# R9A09G057H register map
Vendor: Renesas Electronics; File version: 1.0
Registers are 32-bit, read-write, no defined reset value unless marked. A register's access mark holds for its fields unless they carry their own. Offsets are from the block's base; [hi:lo] are bit positions; {n}, {i} and the like mark numbered series; 'fields as' and 'values as' point back to an identical list.

## R_SYSC — IO define file for sysc.
Base 0x10430000
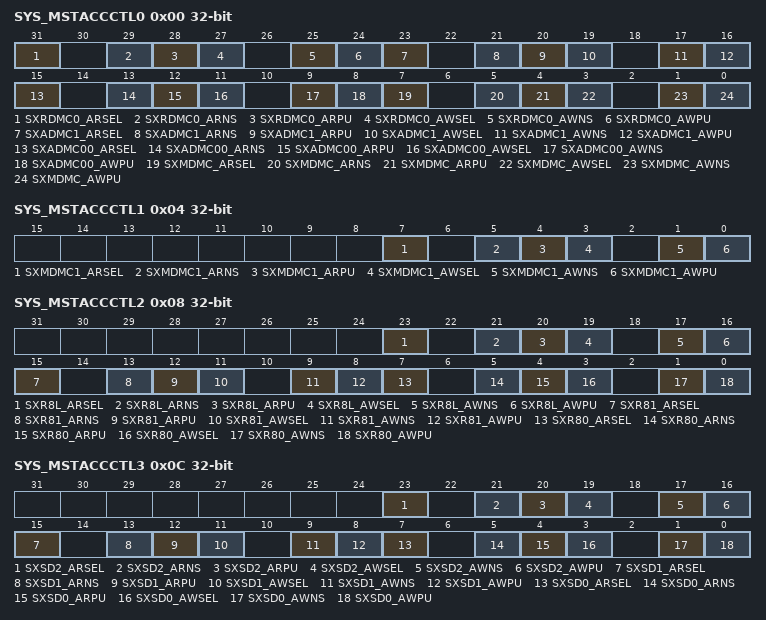
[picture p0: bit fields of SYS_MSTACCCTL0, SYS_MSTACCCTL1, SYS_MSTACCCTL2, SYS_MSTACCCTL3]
0x00 SYS_MSTACCCTL0
  [31] SXRDMC0_ARSEL, [29] SXRDMC0_ARNS, [28] SXRDMC0_ARPU, [27] SXRDMC0_AWSEL, [25] SXRDMC0_AWNS, [24] SXRDMC0_AWPU, [23] SXADMC1_ARSEL, [21] SXADMC1_ARNS, [20] SXADMC1_ARPU, [19] SXADMC1_AWSEL, [17] SXADMC1_AWNS, [16] SXADMC1_AWPU, [15] SXADMC00_ARSEL, [13] SXADMC00_ARNS, [12] SXADMC00_ARPU, [11] SXADMC00_AWSEL, [9] SXADMC00_AWNS, [8] SXADMC00_AWPU, [7] SXMDMC_ARSEL, [5] SXMDMC_ARNS, [4] SXMDMC_ARPU, [3] SXMDMC_AWSEL, [1] SXMDMC_AWNS, [0] SXMDMC_AWPU
0x04 SYS_MSTACCCTL1
  [7] SXMDMC1_ARSEL, [5] SXMDMC1_ARNS, [4] SXMDMC1_ARPU, [3] SXMDMC1_AWSEL, [1] SXMDMC1_AWNS, [0] SXMDMC1_AWPU
0x08 SYS_MSTACCCTL2
  [23] SXR8L_ARSEL, [21] SXR8L_ARNS, [20] SXR8L_ARPU, [19] SXR8L_AWSEL, [17] SXR8L_AWNS, [16] SXR8L_AWPU, [15] SXR81_ARSEL, [13] SXR81_ARNS, [12] SXR81_ARPU, [11] SXR81_AWSEL, [9] SXR81_AWNS, [8] SXR81_AWPU, [7] SXR80_ARSEL, [5] SXR80_ARNS, [4] SXR80_ARPU, [3] SXR80_AWSEL, [1] SXR80_AWNS, [0] SXR80_AWPU
0x0C SYS_MSTACCCTL3
  [23] SXSD2_ARSEL, [21] SXSD2_ARNS, [20] SXSD2_ARPU, [19] SXSD2_AWSEL, [17] SXSD2_AWNS, [16] SXSD2_AWPU, [15] SXSD1_ARSEL, [13] SXSD1_ARNS, [12] SXSD1_ARPU, [11] SXSD1_AWSEL, [9] SXSD1_AWNS, [8] SXSD1_AWPU, [7] SXSD0_ARSEL, [5] SXSD0_ARNS, [4] SXSD0_ARPU, [3] SXSD0_AWSEL, [1] SXSD0_AWNS, [0] SXSD0_AWPU
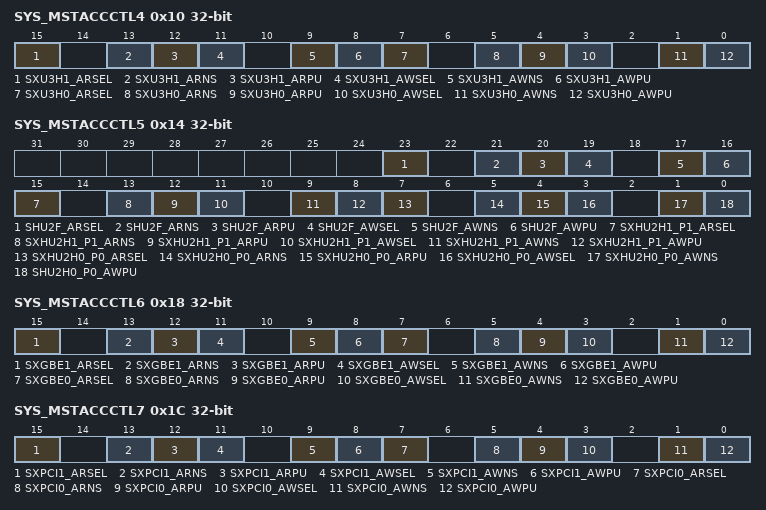
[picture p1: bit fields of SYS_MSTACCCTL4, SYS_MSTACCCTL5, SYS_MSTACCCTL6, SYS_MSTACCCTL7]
0x10 SYS_MSTACCCTL4
  [15] SXU3H1_ARSEL, [13] SXU3H1_ARNS, [12] SXU3H1_ARPU, [11] SXU3H1_AWSEL, [9] SXU3H1_AWNS, [8] SXU3H1_AWPU, [7] SXU3H0_ARSEL, [5] SXU3H0_ARNS, [4] SXU3H0_ARPU, [3] SXU3H0_AWSEL, [1] SXU3H0_AWNS, [0] SXU3H0_AWPU
0x14 SYS_MSTACCCTL5
  [23] SHU2F_ARSEL, [21] SHU2F_ARNS, [20] SHU2F_ARPU, [19] SHU2F_AWSEL, [17] SHU2F_AWNS, [16] SHU2F_AWPU, [15] SXHU2H1_P1_ARSEL, [13] SXHU2H1_P1_ARNS, [12] SXHU2H1_P1_ARPU, [11] SXHU2H1_P1_AWSEL, [9] SXHU2H1_P1_AWNS, [8] SXHU2H1_P1_AWPU, [7] SXHU2H0_P0_ARSEL, [5] SXHU2H0_P0_ARNS, [4] SXHU2H0_P0_ARPU, [3] SXHU2H0_P0_AWSEL, [1] SXHU2H0_P0_AWNS, [0] SHU2H0_P0_AWPU
0x18 SYS_MSTACCCTL6
  [15] SXGBE1_ARSEL, [13] SXGBE1_ARNS, [12] SXGBE1_ARPU, [11] SXGBE1_AWSEL, [9] SXGBE1_AWNS, [8] SXGBE1_AWPU, [7] SXGBE0_ARSEL, [5] SXGBE0_ARNS, [4] SXGBE0_ARPU, [3] SXGBE0_AWSEL, [1] SXGBE0_AWNS, [0] SXGBE0_AWPU
0x1C SYS_MSTACCCTL7
  [15] SXPCI1_ARSEL, [13] SXPCI1_ARNS, [12] SXPCI1_ARPU, [11] SXPCI1_AWSEL, [9] SXPCI1_AWNS, [8] SXPCI1_AWPU, [7] SXPCI0_ARSEL, [5] SXPCI0_ARNS, [4] SXPCI0_ARPU, [3] SXPCI0_AWSEL, [1] SXPCI0_AWNS, [0] SXPCI0_AWPU
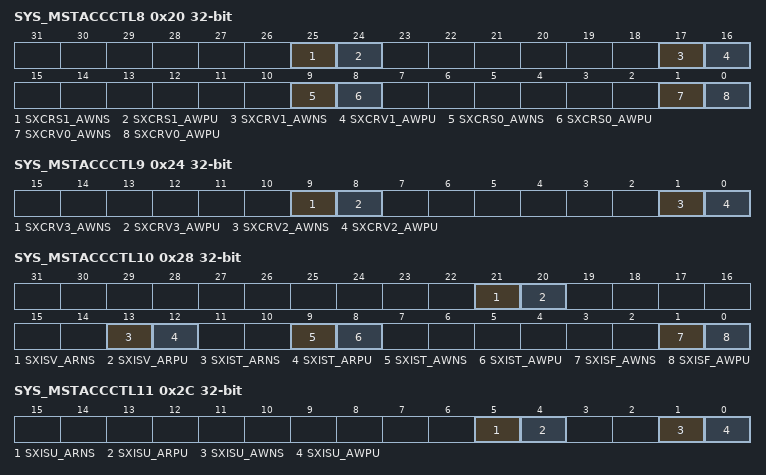
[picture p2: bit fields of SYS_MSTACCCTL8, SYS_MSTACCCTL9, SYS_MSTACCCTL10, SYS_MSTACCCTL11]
0x20 SYS_MSTACCCTL8
  [25] SXCRS1_AWNS, [24] SXCRS1_AWPU, [17] SXCRV1_AWNS, [16] SXCRV1_AWPU, [9] SXCRS0_AWNS, [8] SXCRS0_AWPU, [1] SXCRV0_AWNS, [0] SXCRV0_AWPU
0x24 SYS_MSTACCCTL9
  [9] SXCRV3_AWNS, [8] SXCRV3_AWPU, [1] SXCRV2_AWNS, [0] SXCRV2_AWPU
0x28 SYS_MSTACCCTL10
  [21] SXISV_ARNS, [20] SXISV_ARPU, [13] SXIST_ARNS, [12] SXIST_ARPU, [9] SXIST_AWNS, [8] SXIST_AWPU, [1] SXISF_AWNS, [0] SXISF_AWPU
0x2C SYS_MSTACCCTL11
  [5] SXISU_ARNS, [4] SXISU_ARPU, [1] SXISU_AWNS, [0] SXISU_AWPU
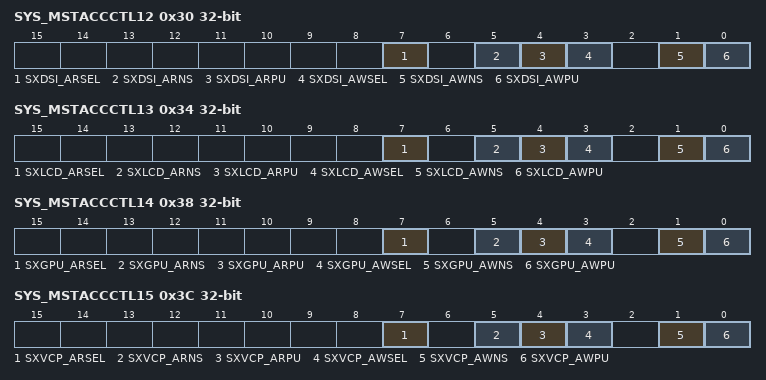
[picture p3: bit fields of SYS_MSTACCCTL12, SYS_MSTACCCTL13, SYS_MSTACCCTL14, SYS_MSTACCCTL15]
0x30 SYS_MSTACCCTL12
  [7] SXDSI_ARSEL, [5] SXDSI_ARNS, [4] SXDSI_ARPU, [3] SXDSI_AWSEL, [1] SXDSI_AWNS, [0] SXDSI_AWPU
0x34 SYS_MSTACCCTL13
  [7] SXLCD_ARSEL, [5] SXLCD_ARNS, [4] SXLCD_ARPU, [3] SXLCD_AWSEL, [1] SXLCD_AWNS, [0] SXLCD_AWPU
0x38 SYS_MSTACCCTL14
  [7] SXGPU_ARSEL, [5] SXGPU_ARNS, [4] SXGPU_ARPU, [3] SXGPU_AWSEL, [1] SXGPU_AWNS, [0] SXGPU_AWPU
0x3C SYS_MSTACCCTL15
  [7] SXVCP_ARSEL, [5] SXVCP_ARNS, [4] SXVCP_ARPU, [3] SXVCP_AWSEL, [1] SXVCP_AWNS, [0] SXVCP_AWPU
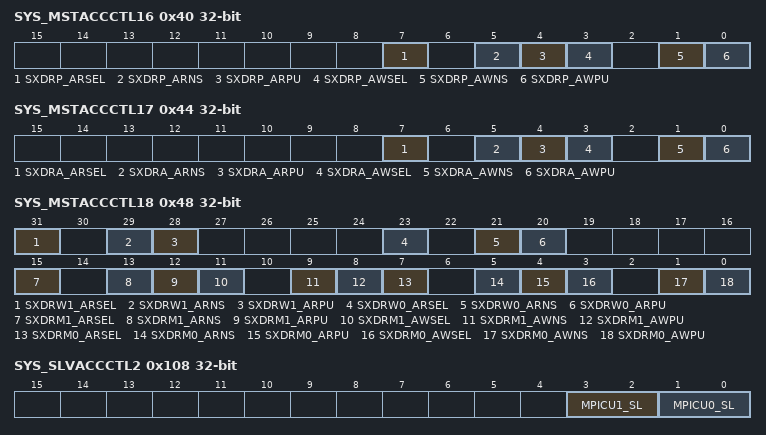
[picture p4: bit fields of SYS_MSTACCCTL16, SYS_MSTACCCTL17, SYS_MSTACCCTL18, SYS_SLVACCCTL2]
0x40 SYS_MSTACCCTL16
  [7] SXDRP_ARSEL, [5] SXDRP_ARNS, [4] SXDRP_ARPU, [3] SXDRP_AWSEL, [1] SXDRP_AWNS, [0] SXDRP_AWPU
0x44 SYS_MSTACCCTL17
  [7] SXDRA_ARSEL, [5] SXDRA_ARNS, [4] SXDRA_ARPU, [3] SXDRA_AWSEL, [1] SXDRA_AWNS, [0] SXDRA_AWPU
0x48 SYS_MSTACCCTL18
  [31] SXDRW1_ARSEL, [29] SXDRW1_ARNS, [28] SXDRW1_ARPU, [23] SXDRW0_ARSEL, [21] SXDRW0_ARNS, [20] SXDRW0_ARPU, [15] SXDRM1_ARSEL, [13] SXDRM1_ARNS, [12] SXDRM1_ARPU, [11] SXDRM1_AWSEL, [9] SXDRM1_AWNS, [8] SXDRM1_AWPU, [7] SXDRM0_ARSEL, [5] SXDRM0_ARNS, [4] SXDRM0_ARPU, [3] SXDRM0_AWSEL, [1] SXDRM0_AWNS, [0] SXDRM0_AWPU
0x100 SYS_SLVACCCTL0
  [1:0] MPCPG_SL
0x104 SYS_SLVACCCTL1 ro
  [1:0] MPSYS_SL
0x108 SYS_SLVACCCTL2
  [3:2] MPICU1_SL, [1:0] MPICU0_SL
0x10C SYS_SLVACCCTL3
  [1:0] MXMDMC_SL
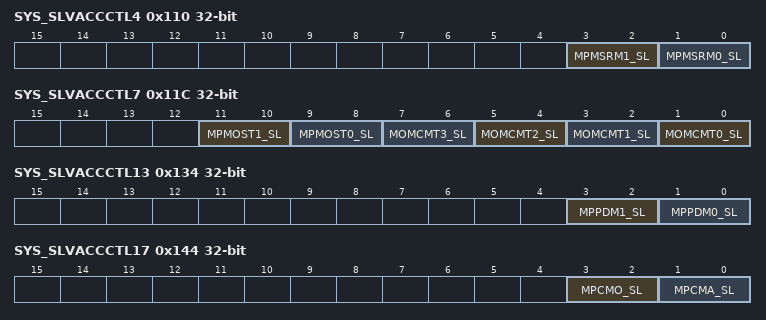
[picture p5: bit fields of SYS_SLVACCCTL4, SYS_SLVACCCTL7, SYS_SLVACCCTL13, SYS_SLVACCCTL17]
0x110 SYS_SLVACCCTL4
  [3:2] MPMSRM1_SL, [1:0] MPMSRM0_SL
0x114 SYS_SLVACCCTL5
  [1:0] MPCST_SL
0x118 SYS_SLVACCCTL6
  [1:0] MPMHU_SL
0x11C SYS_SLVACCCTL7
  [11:10] MPMOST1_SL, [9:8] MPMOST0_SL, [2n+1:2n] MOMCMT{n}_SL (n=0..3)
0x120 SYS_SLVACCCTL8
  [1:0] MOMWDT_SL
0x124 SYS_SLVACCCTL9
  [1:0] MORTC_SL
0x128 SYS_SLVACCCTL10
  [1:0] MORTR_SL
0x12C SYS_SLVACCCTL11
  [1:0] SPI_REG_SL
0x130 SYS_SLVACCCTL12
  [1:0] MHGPO_SL
0x134 SYS_SLVACCCTL13
  [3:2] MPPDM1_SL, [1:0] MPPDM0_SL
0x138 SYS_SLVACCCTL14
  [1:0] MOADC_SL
0x13C SYS_SLVACCCTL15
  [1:0] MPMTSU0_SL
0x144 SYS_SLVACCCTL17
  [3:2] MPCMO_SL, [1:0] MPCMA_SL
0x14C SYS_SLVACCCTL19
  [1:0] MOSCF_SL
0x150 SYS_SLVACCCTL20
  [1:0] MOMI2C_SL
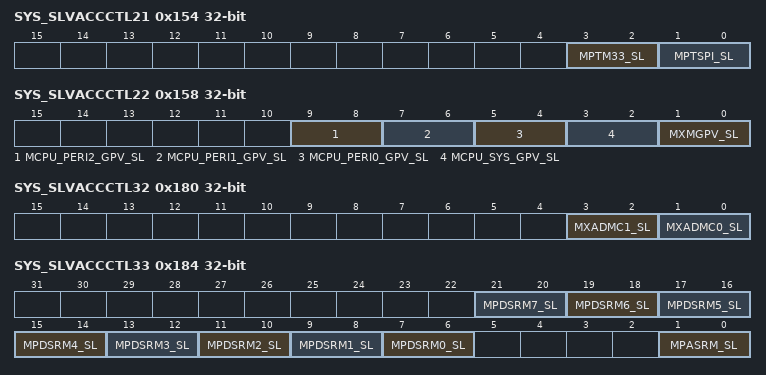
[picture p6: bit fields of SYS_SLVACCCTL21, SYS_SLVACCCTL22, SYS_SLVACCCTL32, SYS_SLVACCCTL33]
0x154 SYS_SLVACCCTL21
  [3:2] MPTM33_SL, [1:0] MPTSPI_SL
0x158 SYS_SLVACCCTL22
  [9:8] MCPU_PERI2_GPV_SL, [7:6] MCPU_PERI1_GPV_SL, [5:4] MCPU_PERI0_GPV_SL, [3:2] MCPU_SYS_GPV_SL, [1:0] MXMGPV_SL
0x180 SYS_SLVACCCTL32
  [3:2] MXADMC1_SL, [1:0] MXADMC0_SL
0x184 SYS_SLVACCCTL33
  [2n+7:2n+6] MPDSRM{n}_SL (n=0..7), [1:0] MPASRM_SL
0x18C SYS_SLVACCCTL35
  [1:0] MPSYC_SL
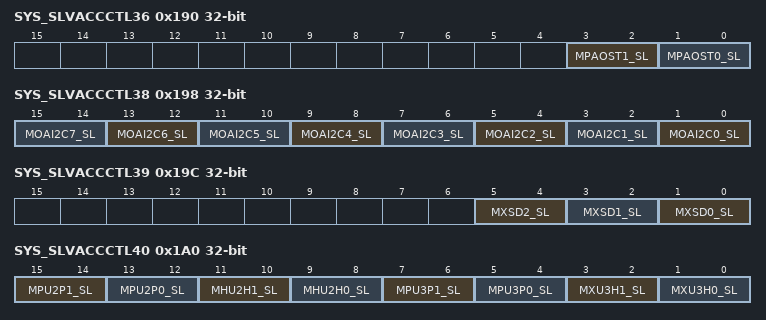
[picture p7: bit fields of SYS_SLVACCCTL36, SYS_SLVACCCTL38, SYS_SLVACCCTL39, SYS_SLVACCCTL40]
0x190 SYS_SLVACCCTL36
  [3:2] MPAOST1_SL, [1:0] MPAOST0_SL
0x194 SYS_SLVACCCTL37
  [1:0] MOAWDT_SL
0x198 SYS_SLVACCCTL38
  [2n+1:2n] MOAI2C{n}_SL (n=0..7)
0x19C SYS_SLVACCCTL39
  [5:4] MXSD2_SL, [3:2] MXSD1_SL, [1:0] MXSD0_SL
0x1A0 SYS_SLVACCCTL40
  [15:14] MPU2P1_SL, [13:12] MPU2P0_SL, [11:10] MHU2H1_SL, [9:8] MHU2H0_SL, [7:6] MPU3P1_SL, [5:4] MPU3P0_SL, [3:2] MXU3H1_SL, [1:0] MXU3H0_SL
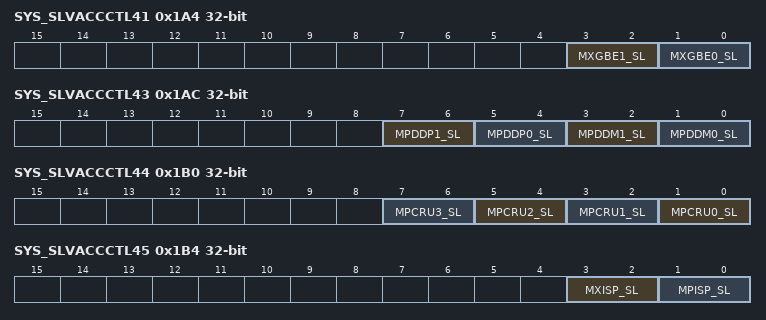
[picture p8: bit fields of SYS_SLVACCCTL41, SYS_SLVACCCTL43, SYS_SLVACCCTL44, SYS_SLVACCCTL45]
0x1A4 SYS_SLVACCCTL41
  [3:2] MXGBE1_SL, [1:0] MXGBE0_SL
0x1AC SYS_SLVACCCTL43
  [7:6] MPDDP1_SL, [5:4] MPDDP0_SL, [3:2] MPDDM1_SL, [1:0] MPDDM0_SL
0x1B0 SYS_SLVACCCTL44
  [2n+1:2n] MPCRU{n}_SL (n=0..3)
0x1B4 SYS_SLVACCCTL45
  [3:2] MXISP_SL, [1:0] MPISP_SL
0x1B8 SYS_SLVACCCTL46
  [1:0] MPISU_SL
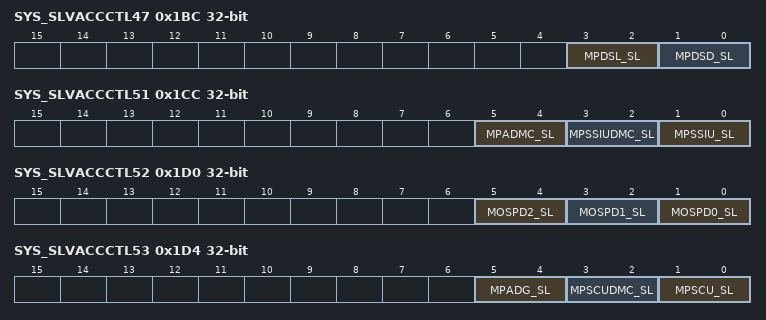
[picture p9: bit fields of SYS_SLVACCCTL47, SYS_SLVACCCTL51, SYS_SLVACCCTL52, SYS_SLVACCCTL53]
0x1BC SYS_SLVACCCTL47
  [3:2] MPDSL_SL, [1:0] MPDSD_SL
0x1C0 SYS_SLVACCCTL48
  [1:0] MPLCD_SL
0x1C4 SYS_SLVACCCTL49
  [1:0] MXGPU_SL
0x1C8 SYS_SLVACCCTL50
  [1:0] MPVCC_SL
0x1CC SYS_SLVACCCTL51
  [5:4] MPADMC_SL, [3:2] MPSSIUDMC_SL, [1:0] MPSSIU_SL
0x1D0 SYS_SLVACCCTL52
  [5:4] MOSPD2_SL, [3:2] MOSPD1_SL, [1:0] MOSPD0_SL
0x1D4 SYS_SLVACCCTL53
  [5:4] MPADG_SL, [3:2] MPSCUDMC_SL, [1:0] MPSCU_SL
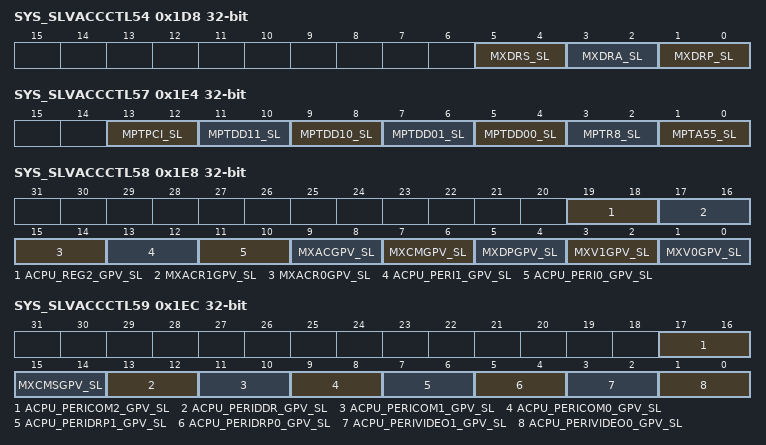
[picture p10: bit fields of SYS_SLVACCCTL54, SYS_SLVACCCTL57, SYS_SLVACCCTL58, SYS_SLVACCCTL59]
0x1D8 SYS_SLVACCCTL54
  [5:4] MXDRS_SL, [3:2] MXDRA_SL, [1:0] MXDRP_SL
0x1DC SYS_SLVACCCTL55
  [1:0] MXGIC_SL
0x1E0 SYS_SLVACCCTL56
  [1:0] MPMTSU1_SL
0x1E4 SYS_SLVACCCTL57
  [13:12] MPTPCI_SL, [11:10] MPTDD11_SL, [9:8] MPTDD10_SL, [7:6] MPTDD01_SL, [5:4] MPTDD00_SL, [3:2] MPTR8_SL, [1:0] MPTA55_SL
0x1E8 SYS_SLVACCCTL58
  [19:18] ACPU_REG2_GPV_SL, [17:16] MXACR1GPV_SL, [15:14] MXACR0GPV_SL, [13:12] ACPU_PERI1_GPV_SL, [11:10] ACPU_PERI0_GPV_SL, [9:8] MXACGPV_SL, [7:6] MXCMGPV_SL, [5:4] MXDPGPV_SL, [3:2] MXV1GPV_SL, [1:0] MXV0GPV_SL
0x1EC SYS_SLVACCCTL59
  [17:16] ACPU_PERICOM2_GPV_SL, [15:14] MXCMSGPV_SL, [13:12] ACPU_PERIDDR_GPV_SL, [11:10] ACPU_PERICOM1_GPV_SL, [9:8] ACPU_PERICOM0_GPV_SL, [7:6] ACPU_PERIDRP1_GPV_SL, [5:4] ACPU_PERIDRP0_GPV_SL, [3:2] ACPU_PERIVIDEO1_GPV_SL, [1:0] ACPU_PERIVIDEO0_GPV_SL
0x200 SYS_SLVACCCTL64
  [1:0] MOCRC_SL
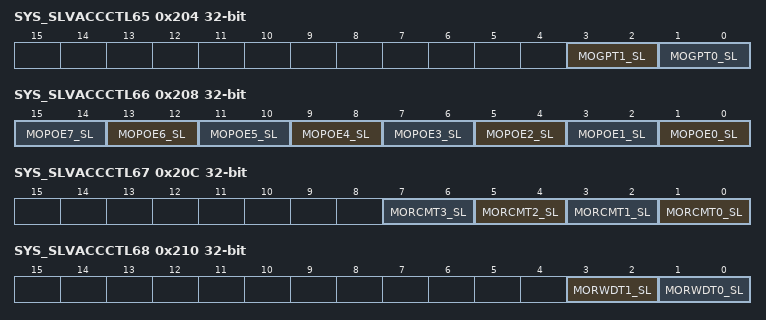
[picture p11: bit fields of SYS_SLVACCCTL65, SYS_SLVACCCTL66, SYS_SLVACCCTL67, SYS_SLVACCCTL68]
0x204 SYS_SLVACCCTL65
  [3:2] MOGPT1_SL, [1:0] MOGPT0_SL
0x208 SYS_SLVACCCTL66
  [2n+1:2n] MOPOE{n}_SL (n=0..7)
0x20C SYS_SLVACCCTL67
  [2n+1:2n] MORCMT{n}_SL (n=0..3)
0x210 SYS_SLVACCCTL68
  [3:2] MORWDT1_SL, [1:0] MORWDT0_SL
0x240 SYS_SLVACCCTL80
  [1:0] I3C_SL
0x244 SYS_SLVACCCTL81
  [1:0] CANFD_SL
0x248 SYS_SLVACCCTL82
  [1:0] RCPU_SRAM_SL
0x260 SYS_SLVACCCTL88
  [1:0] RCPU_SL
0x264 SYS_SLVACCCTL89
  [1:0] MCPU_SL
0x26C SYS_SLVACCCTL91
  [1:0] LSI_SL
0x270 SYS_SLVACCCTL92
  [1:0] AOF_SL
0x274 SYS_SLVACCCTL93
  [1:0] GPREG_SL
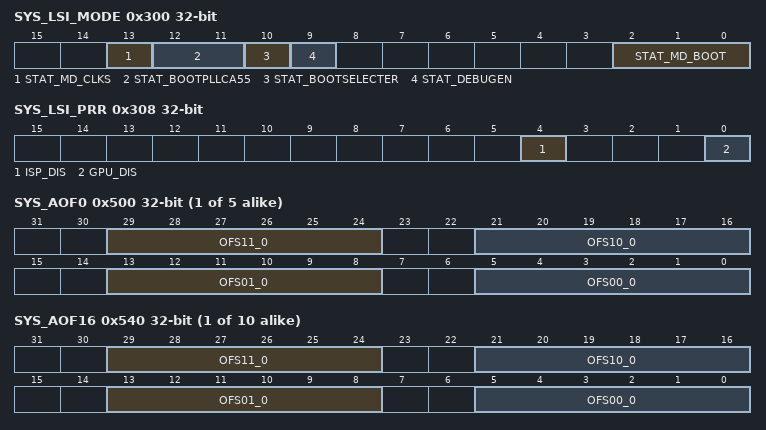
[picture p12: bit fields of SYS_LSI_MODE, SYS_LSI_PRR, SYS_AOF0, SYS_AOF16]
0x300 SYS_LSI_MODE ro
  [13] STAT_MD_CLKS, [12:11] STAT_BOOTPLLCA55, [10] STAT_BOOTSELECTER, [9] STAT_DEBUGEN, [2:0] STAT_MD_BOOT
0x304 SYS_LSI_DEVID ro
  [31:0] DEV_ID
0x308 SYS_LSI_PRR ro
  [4] ISP_DIS, [0] GPU_DIS
0x320 SYS_LSI_OTPTSU0TRMVAL0 ro
  [31:0] TSU0_TRMVAL0
0x324 SYS_LSI_OTPTSU0TRMVAL1 ro
  [31:0] TSU0_TRMVAL1
0x330 SYS_LSI_OTPTSU1TRMVAL0 ro
  [31:0] TSU1_TRMVAL0
0x334 SYS_LSI_OTPTSU1TRMVAL1 ro
  [31:0] TSU1_TRMVAL1
{0x500+4i} SYS_AOF{i} (i=0..4)
  [29:24] OFS11_{i}, [21:16] OFS10_{i}, [13:8] OFS01_{i}, [5:0] OFS00_{i}
{0x500+4i} SYS_AOF{i} (i=16..25)
  fields as SYS_AOF0
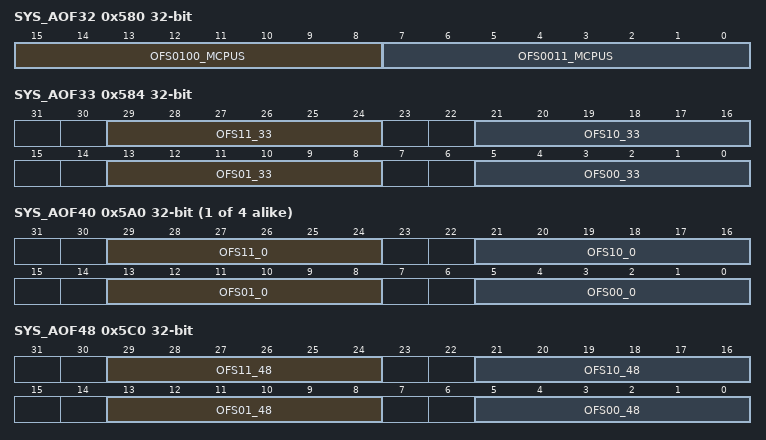
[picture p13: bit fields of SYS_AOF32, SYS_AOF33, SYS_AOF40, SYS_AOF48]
0x580 SYS_AOF32
  [15:8] OFS0100_MCPUS, [7:0] OFS0011_MCPUS
0x584 SYS_AOF33
  [29:24] OFS11_33, [21:16] OFS10_33, [13:8] OFS01_33, [5:0] OFS00_33
{0x500+4i} SYS_AOF{i} (i=40..43)
  fields as SYS_AOF0
0x5C0 SYS_AOF48
  [29:24] OFS11_48, [21:16] OFS10_48, [13:8] OFS01_48, [5:0] OFS00_48
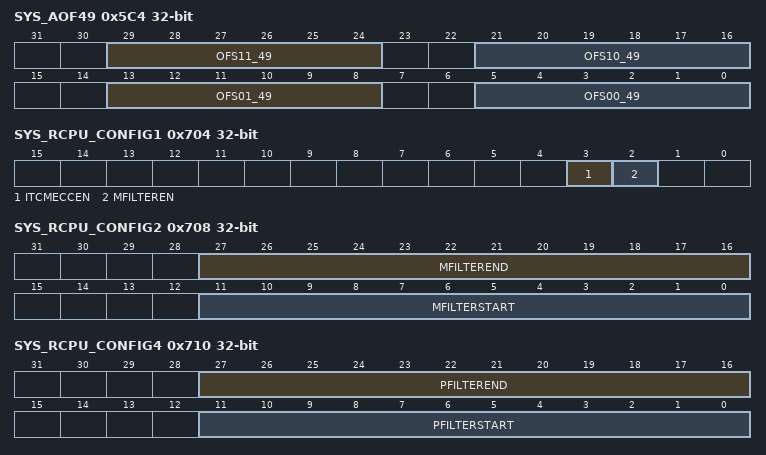
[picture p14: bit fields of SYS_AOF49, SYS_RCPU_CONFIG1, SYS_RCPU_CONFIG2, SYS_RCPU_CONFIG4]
0x5C4 SYS_AOF49
  [29:24] OFS11_49, [21:16] OFS10_49, [13:8] OFS01_49, [5:0] OFS00_49
0x600 SYS_ACPU_CFG_SMPL
  [7:0] ASTARTMPL
0x604 SYS_ACPU_CFG_SMPH
  [31:20] ASTARTMPH
0x608 SYS_ACPU_CFG_EMPL
  [31:20] AENDMPLMPL
0x60C SYS_ACPU_CFG_EMPH
  [7:0] AENDMPH
{0x624+8i} SYS_ACPU_CFG_RVAL{i} (i=0..3)
  [31:2] RVBARADDRL{i}
{0x628+8i} SYS_ACPU_CFG_RVAH{i} (i=0..3)
  [7:0] RVBARADDRH{i}
0x704 SYS_RCPU_CONFIG1
  [3] ITCMECCEN, [2] MFILTEREN
0x708 SYS_RCPU_CONFIG2
  [27:16] MFILTEREND, [11:0] MFILTERSTART
0x70C SYS_RCPU_CONFIG3
  [31:13] PERIPHBASE
0x710 SYS_RCPU_CONFIG4
  [27:16] PFILTEREND, [11:0] PFILTERSTART
0x71C SYS_RCPU_CORESTATUS ro
  [24] SCUIDLE, [23:22] PWRCTLO1, [21:20] PWRCTLO0, [9:8] PMUPRIV, [1:0] SMPnAMP
0x80C SYS_MCPU_CFG2
  [31:7] INITSVTOR
0x810 SYS_MCPU_CFG3
  [31:7] INITNSVTOR
0x814 SYS_MCPU_CFG4
  [0] IDAUZERONS
0x818 SYS_MCPU_CFG5
  [1] LOCKNSVTOR, [0] LOCKSVTAIRCR
0x900 SYS_SPI_STAADDCS0 ro
  [31:0] XSPI_STARTADDRCS0
0x904 SYS_SPI_ENDADDCS0 ro
  [31:0] XSPI_ENDADDRCS0
0x908 SYS_SPI_STAADDCS1 ro
  [31:0] XSPI_STARTADDRCS1
0x90C SYS_SPI_ENDADDCS1 ro
  [31:0] XSPI_ENDADDRCS1
{0xB00+0x14*i} SYS_SRAM{i}_ECC (i=0..11)
  [0] VECCEN
{0xB04+0x14*i} SYS_SRAM{i}_EN (i=0..11)
  [1] VLWEN, [0] VCEN
0xC00 SYS_WDT0_CTRL
  [16] WDTSTOPMASK, [0] bp_halted
0xC04 SYS_WDT2_CTRL
  [16] WDTSTOPMASK, [0] bp_halted
0xC08 SYS_WDT3_CTRL
  [16] WDTSTOPMASK, [0] bp_halted
0xC0C SYS_WDT1_CTRL
  [16] WDTSTOPMASK, [0] bp_halted
0xF00 SYS_GBETH0_CFG
  [18:16] PHY_INTF_TYPE, [1:0] MAC_SPEED ro
0xF04 SYS_GBETH1_CFG
  [18:16] PHY_INTF_TYPE, [1:0] MAC_SPEED ro
0x1000 SYS_PCIE_INTX_CH0
  [1] INTX_EP_F1, [0] INTX_EP_F0
0x1004 SYS_PCIE_MSI1_CH0
  [n] UI_EXTMSI_VAL{n} (n=0..4)
0x1008 SYS_PCIE_MSI2_CH0
  [8n+4:8n] UI_EXTMSI_VEC{n} (n=0..3)
0x100C SYS_PCIE_MSI3_CH0
  [4:0] UI_EXTMSI_VEC
0x1010 SYS_PCIE_MSI4_CH0
  [8n+2:8n] UI_EXTMSI_FUNC{n} (n=0..3)
0x1014 SYS_PCIE_MSI5_CH0
  [2:0] UI_EXTMSI_FUNC4
0x1018 SYS_PCIE_PME_CH0
  [9] CFG_PMCSR_PME_STATUS_F1, [8] CFG_PMCSR_PME_STATUS_F0, [0] PME_TIM
0x101C SYS_PCIE_ACK_CH0
  [9] D3_ECENT_ACK_F1, [8] D3_ECENT_ACK_F0, [0] TURN_OFF_EVENT_ACK
0x1020 SYS_PCIE_MISC_CH0
  [19:18] FLR_REQ ro, [17:16] FLR_RESET, [0] ALLOW_ENTER_L1
0x1024 SYS_PCIE_MODE_CH0
  [0] MODE_PORT
0x1030 SYS_PCIE_INTX_CH1
  [1] INTX_EP_F1, [0] INTX_EP_F0
0x1034 SYS_PCIE_MSI1_CH1
  [n] UI_EXTMSI_VAL{n} (n=0..4)
0x1038 SYS_PCIE_MSI2_CH1
  [8n+4:8n] UI_EXTMSI_VEC{n} (n=0..3)
0x103C SYS_PCIE_MSI3_CH1
  [4:0] UI_EXTMSI_VEC4
0x1040 SYS_PCIE_MSI4_CH1
  [8n+2:8n] UI_EXTMSI_FUNC{n} (n=0..3)
0x1044 SYS_PCIE_MSI5_CH1
  [2:1] UI_EXTMSI_FUNC4, [0] UI_EXTMSI_FUNC40
0x1048 SYS_PCIE_PME_CH1
  fields as SYS_PCIE_PME_CH0
0x104C SYS_PCIE_ACK_CH1
  [9] D3_ECENT_ACK_F1, [8] D3_ECENT_ACK_F0, [0] TURN_OFF_EVENT_ACK
0x1050 SYS_PCIE_MISC_CH1
  [19:18] FLR_REQ ro, [17:16] FLR_RESET, [0] ALLOW_ENTER_L1
0x1054 SYS_PCIE_MODE_CH1
  [9:8] LINK_MASTER, [0] MODE_PORT
0x1060 SYS_PCIE_MODE
  [9:8] LINK_MASTER
0x1600 SYS_ADC_CFG
  [0] sy_mstp_ada
{0x1700+4i} SYS_GPREG_{i} (i=0..3)
  [31:0] CPREG{i}
